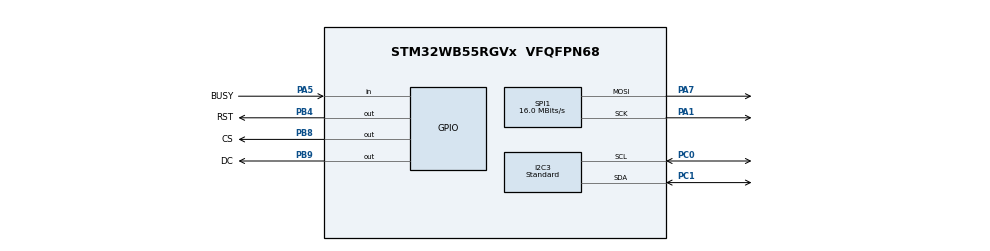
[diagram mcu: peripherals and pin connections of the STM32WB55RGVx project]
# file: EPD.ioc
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Dma.Request0=SPI1_TX
Dma.SPI1_TX.0.Direction=DMA_MEMORY_TO_PERIPH
Dma.SPI1_TX.0.EventEnable=DISABLE
Dma.SPI1_TX.0.Instance=DMA1_Channel1
Dma.SPI1_TX.0.MemDataAlignment=DMA_MDATAALIGN_BYTE
Dma.SPI1_TX.0.MemInc=DMA_MINC_ENABLE
Dma.SPI1_TX.0.Mode=DMA_NORMAL
Dma.SPI1_TX.0.PeriphDataAlignment=DMA_PDATAALIGN_BYTE
Dma.SPI1_TX.0.PeriphInc=DMA_PINC_DISABLE
Dma.SPI1_TX.0.Polarity=HAL_DMAMUX_REQ_GEN_RISING
Dma.SPI1_TX.0.Priority=DMA_PRIORITY_VERY_HIGH
Dma.SPI1_TX.0.RequestNumber=1
Dma.SPI1_TX.0.SignalID=NONE
Dma.SPI1_TX.0.SyncEnable=DISABLE
Dma.SPI1_TX.0.SyncPolarity=HAL_DMAMUX_SYNC_NO_EVENT
Dma.SPI1_TX.0.SyncRequestNumber=1
Dma.SPI1_TX.0.SyncSignalID=NONE
I2C3.I2C_Speed_Mode=I2C_Standard
I2C3.Timing=0x00B07CB4
Mcu.Family=STM32WB
Mcu.Name=STM32WB55RGVx
Mcu.Package=VFQFPN68
NVIC.DMA1_Channel1_IRQn=true\:0\:0\:false\:false\:true\:false\:true\:true
NVIC.PriorityGroup=NVIC_PRIORITYGROUP_4
NVIC.RTC_WKUP_IRQn=true\:0\:0\:false\:false\:true\:true\:true\:true
NVIC.TAMP_STAMP_LSECSS_IRQn=true\:0\:0\:false\:false\:true\:true\:true\:true
OSC_IN.GPIO_Label=RCC_OSC_IN
OSC_IN.Mode=HSE-External-Oscillator
OSC_IN.Signal=RCC_OSC_IN
OSC_OUT.GPIO_Label=RCC_OSC_OUT
OSC_OUT.Mode=HSE-External-Oscillator
OSC_OUT.Signal=RCC_OSC_OUT
P-NUCLEO-WB55-NUCLEO.BUTTON=1
P-NUCLEO-WB55-NUCLEO.BUTTON2=1
P-NUCLEO-WB55-NUCLEO.BUTTON3=1
P-NUCLEO-WB55-NUCLEO.LD1=true
P-NUCLEO-WB55-NUCLEO.LD2=true
P-NUCLEO-WB55-NUCLEO.LD3=true
P-NUCLEO-WB55-NUCLEO.VCP=true
PA1.Mode=TX_Only_Simplex_Unidirect_Master
PA1.Signal=SPI1_SCK
PA11.GPIO_Label=USB_DM
PA11.Signal=USB_DM
PA12.GPIO_Label=USB_DP
PA12.Signal=USB_DP
PA13.GPIO_Label=JTMS
PA13.Mode=Serial_Wire
PA13.Signal=SYS_JTMS-SWDIO
PA14.GPIO_Label=JTCK
PA14.Mode=Serial_Wire
PA14.Signal=SYS_JTCK-SWCLK
PA5.GPIO_Label=BUSY
PA5.Signal=GPIO_Input
PA7.Mode=TX_Only_Simplex_Unidirect_Master
PA7.Signal=SPI1_MOSI
PB3.GPIO_Label=JTDO
PB3.Signal=SYS_JTDO-SWO
PB4.GPIO_Label=RST
PB4.PinState=GPIO_PIN_SET
PB4.Signal=GPIO_Output
PB6.Signal=USART1_TX
PB7.Signal=USART1_RX
PB8.GPIO_FM8=SYSCFG_FASTMODEPLUS_PB8
PB8.GPIO_Label=CS
PB8.GPIO_Speed=GPIO_SPEED_FREQ_VERY_HIGH
PB8.PinState=GPIO_PIN_SET
PB8.Signal=GPIO_Output
PB9.GPIO_FM9=SYSCFG_FASTMODEPLUS_PB9
PB9.GPIO_Label=DC
PB9.GPIO_Speed=GPIO_SPEED_FREQ_VERY_HIGH
PB9.Signal=GPIO_Output
PC0.Mode=I2C
PC0.Signal=I2C3_SCL
PC1.Mode=I2C
PC1.Signal=I2C3_SDA
PC13.GPIO_Label=SYS_WKUP2
PC13.Signal=SYS_WKUP2
PC14-OSC32_IN.GPIO_Label=RCC_OSC32_IN
PC14-OSC32_IN.Mode=LSE-External-Oscillator
PC14-OSC32_IN.Signal=RCC_OSC32_IN
PC15-OSC32_OUT.GPIO_Label=RCC_OSC32_OUT
PC15-OSC32_OUT.Mode=LSE-External-Oscillator
PC15-OSC32_OUT.Signal=RCC_OSC32_OUT
ProjectManager.HeapSize=0x4000
ProjectManager.StackSize=0x1000
ProjectManager.TargetToolchain=STM32CubeIDE
RCC.ADCFreq_Value=128000000
RCC.AHBFreq_Value=32000000
RCC.APB1Freq_Value=32000000
RCC.APB1TimFreq_Value=32000000
RCC.APB2Freq_Value=32000000
RCC.APB2TimFreq_Value=32000000
RCC.APB3Freq_Value=16000000
RCC.CortexFreq_Value=32000000
RCC.EnableCSSLSE=true
RCC.HCLKFreq_Value=32000000
RCC.HSE_VALUE=32000000
RCC.HSI48_VALUE=48000000
RCC.HSI_VALUE=16000000
RCC.MSIClockRange=RCC_MSIRANGE_10
RCC.RTCClockSelection=RCC_RTCCLKSOURCE_LSE
RCC.SMPSCLockSelection=RCC_SMPSCLKSOURCE_HSI
RCC.SMPSCLockSelectionVirtual=RCC_SMPSCLKSOURCE_HSI
RCC.SMPSCLockSelectionVirtualVirtual=RCC_SMPSCLKSOURCE_HSI
RCC.SMPSDivider=1
RCC.SYSCLKFreq_VALUE=32000000
RCC.USBFreq_Value=128000000
RCC.VCOOutputFreq_Value=256000000
SPI1.CalculateBaudRate=16.0 MBits/s
SPI1.DataSize=SPI_DATASIZE_8BIT
SPI1.Direction=SPI_DIRECTION_2LINES
SPI1.Mode=SPI_MODE_MASTER
SPI1.NSSPMode=SPI_NSS_PULSE_DISABLE
SPI1.VirtualType=VM_MASTER
VP_MEMORYMAP_VS_MEMORYMAP.Mode=CurAppReg
VP_P-NUCLEO-WB55-NUCLEO_VS_BSP_COMMON.Mode=COMMON
VP_RTC_VS_RTC_Activate.Mode=RTC_Enabled
VP_RTC_VS_RTC_WakeUp_intern.Mode=WakeUp
board=P-NUCLEO-WB55-NUCLEO

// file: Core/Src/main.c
/* USER CODE BEGIN Header */
/**
  ******************************************************************************
  * @file           : main.c
  * @brief          : Main program body
  ******************************************************************************
  * @attention
  *
  * Copyright (c) 2025 STMicroelectronics.
  * All rights reserved.
  *
  * This software is licensed under terms that can be found in the LICENSE file
  * in the root directory of this software component.
  * If no LICENSE file comes with this software, it is provided AS-IS.
  *
  ******************************************************************************
  */
/* USER CODE END Header */
#include "main.h"

/* USER CODE BEGIN Includes */
#include <stdint.h>
#include <stdbool.h>
#include <string.h>
#include "lvgl.h"
/* USER CODE END Includes */

/* USER CODE BEGIN PD */
// Function Prototypes
void EPD_Delay_ms(uint32_t ms);
void EPD_Read_Busy(void);
void EPD_Write_Command(uint8_t command);
void EPD_Write_Data(uint8_t data);
void EPD_Init(void); // New Initialization function
void EPD_Update_and_Deepsleep_full_update(void);
void EPD_Test_Sequence(void);
void enter_stop2_mode(void);

// SHT45 I2C Driver
#define SHT45_I2C_ADDRESS 0x44
#define SHT45_CMD_MEASURE_HIGH_PRECISION 0xFD

HAL_StatusTypeDef SHT45_Read_Temp_Humidity(float *temperature, float *humidity);
/* USER CODE END PD */

COM_InitTypeDef BspCOMInit;
I2C_HandleTypeDef hi2c3;

RTC_HandleTypeDef hrtc;

SPI_HandleTypeDef hspi1;
DMA_HandleTypeDef hdma_spi1_tx;

/* USER CODE BEGIN PV */
static volatile int update_chunks_remaining = 0;
static volatile bool full_update_in_progress = false;
static uint32_t last_sensor_read_time = 0;
static float current_temperature = 0.0f;
static float current_humidity = 0.0f;
/* USER CODE END PV */

void SystemClock_Config(void);
void PeriphCommonClock_Config(void);
static void MX_GPIO_Init(void);
static void MX_DMA_Init(void);
static void MX_SPI1_Init(void);
static void MX_RTC_Init(void);
static void MX_I2C3_Init(void);

/* USER CODE BEGIN 0 */

/* LVGL EPD Display Driver */
static lv_disp_drv_t disp_drv;
static lv_disp_draw_buf_t draw_buf;
static lv_color_t buf_1[250 * 122]; /* Display buffer - 250 pixels wide, 122 lines */

/**
  * @brief  Flush the content of the internal buffer to the EPD
  * @param  drv: pointer to a display driver
  * @param  area: pointer to the area to flush
  * @param  color_p: pointer to the color data
  * @retval None
  */
void lv_epd_flush(lv_disp_drv_t * drv, const lv_area_t * area, lv_color_t * color_p)
{
    printf("LVGL Flush: Area (%d,%d)-(%d,%d) Size: %dx%d\n",
           area->x1, area->y1, area->x2, area->y2,
           area->x2 - area->x1 + 1, area->y2 - area->y1 + 1);

    uint32_t x, y;
    uint32_t width = area->x2 - area->x1 + 1;
    uint32_t height = area->y2 - area->y1 + 1;

    // EPD configuration: 122H (horizontal) packed into bytes, 250V (vertical)
    // LVGL buffer: 122V x 250H (rotated 90 degrees)
    const uint32_t EPD_BYTES_PER_LINE = 16; // 122 pixels / 8 = 15.25 -> 16 bytes

    EPD_Init();
    EPD_Write_Command(0x24); /* Write Black/White RAM */

    // Rotate 90 degrees: LVGL (122V x 250H) -> EPD (122H x 250V)
    // LVGL: top-to-bottom, left-to-right
    // EPD: bottom-up, right-to-left (landscape mode)

    // For each vertical line in EPD (250 lines)
    for(y = 0; y < 250; y++) {
        // For each byte in the horizontal line (16 bytes for 122 pixels)
        for(x = 0; x < EPD_BYTES_PER_LINE; x++) {
            uint8_t byte_data = 0;
            uint32_t bit_pos;

            // Process 8 bits per byte
            for(bit_pos = 0; bit_pos < 8; bit_pos++) {
                uint32_t pixel_x_in_epd = (x * 8 + bit_pos);

                // Only process valid pixels within 122 horizontal range
                if (pixel_x_in_epd < 122) {
                    // 90-degree rotation mapping:
                    // LVGL x coordinate becomes EPD y coordinate (rotated)
                    // LVGL y coordinate becomes EPD x coordinate (rotated)

                    // Map EPD coordinates to LVGL coordinates:
                    // EPD x (0-121) -> LVGL y (0-121)
                    // EPD y (0-249) -> LVGL x (0-249)

                    // For bottom-up, right-to-left EPD:
                    // - Reverse Y direction (bottom-up): 249 - y
                    // - Reverse X direction (right-to-left): 121 - pixel_x_in_epd

                    uint32_t lvgl_x = 249 - y;  // Reverse Y for bottom-up
                    uint32_t lvgl_y = 121 - pixel_x_in_epd;  // Reverse X for right-to-left

                    // Check if the mapped coordinates are within the current flush area
                    if (lvgl_x >= area->x1 && lvgl_x <= area->x2 &&
                        lvgl_y >= area->y1 && lvgl_y <= area->y2) {

                        // Calculate buffer index in LVGL buffer
                        uint32_t buffer_index = (lvgl_y - area->y1) * width + (lvgl_x - area->x1);

                        if (buffer_index < width * height) {
                            lv_color_t pixel_color = color_p[buffer_index];

                            /* Convert LVGL color to monochrome (1 = white, 0 = black) */
                            if(pixel_color.full != 0) { /* White */
                                // MSB first bit packing
                                byte_data |= (1 << (7 - bit_pos));
                            }
                        }
                    }
                }
            }
            EPD_Write_Data(byte_data);
        }
    }

    EPD_Update_and_Deepsleep_full_update();
    lv_disp_flush_ready(drv);
}

/**
  * @brief  Initialize LVGL with EPD display driver
  * @retval None
  */
void lv_epd_init(void)
{
    /* Debug output */
    printf("Initializing LVGL with EPD driver...\n");

    /* Initialize LVGL */
    lv_init();

    /* Initialize display buffer */
    lv_disp_draw_buf_init(&draw_buf, buf_1, NULL, 250 * 122);

    /* Initialize display driver */
    lv_disp_drv_init(&disp_drv);
    disp_drv.hor_res = 250;
    disp_drv.ver_res = 122;
    disp_drv.flush_cb = lv_epd_flush;
    disp_drv.draw_buf = &draw_buf;
    disp_drv.full_refresh = 1; /* Use full refresh until basic display works */
    disp_drv.direct_mode = 0;

    /* Register the display driver */
    lv_disp_t * disp = lv_disp_drv_register(&disp_drv);

    /* Debug output */
    printf("LVGL display driver registered. Resolution: %dx%d\n", disp_drv.hor_res, disp_drv.ver_res);

    /* Set EPD to monochrome mode */
    lv_disp_set_theme(disp, lv_theme_mono_init(disp, false, LV_FONT_DEFAULT));
}

/**
  * @brief  LVGL task handler - call this periodically in main loop
  * @retval None
  */
void lv_epd_task_handler(void)
{
    static uint32_t counter = 0;
    if(counter++ % 100 == 0) {
        printf("LVGL task handler running...\n");
    }
    lv_task_handler();
}

/**
  * @brief  Create a simple test UI for EPD
  * @retval None
  */
void lv_epd_create_test_ui(void)
{
    /* Debug output */
    printf("Creating LVGL test UI...\n");

    /* Create a simple label */
    lv_obj_t * label = lv_label_create(lv_scr_act());
    lv_label_set_text(label, "Hello");
    lv_obj_set_style_text_font(label, &lv_font_montserrat_16, 0);
    lv_obj_align(label, LV_ALIGN_CENTER, 0, 0);

}

// ... (Private macros and variables remain the same) ...
// ... (EPD_Delay_ms, EPD_Read_Busy, EPD_Write_Command, EPD_Write_Data functions remain the same) ...

/**
  * @brief  Initializes the EPD driver with the required sequence from the datasheet.
  *         This function follows the flow described in section 10.2 of the specification.
  * @retval None
  */
void EPD_Init(void)
{
    // --- 1. HARDWARE RESET SEQUENCE ---
	EPD_Delay_ms(1); // delay >200us
    HAL_GPIO_WritePin(RST_GPIO_Port, RST_Pin, GPIO_PIN_RESET); // RES# low
    EPD_Delay_ms(1); // delay >200us
    HAL_GPIO_WritePin(RST_GPIO_Port, RST_Pin, GPIO_PIN_SET);   // RES# high
    EPD_Delay_ms(1); // delay >200us
    EPD_Read_Busy(); // Wait for busy low

    // --- 2. SOFTWARE RESET ---
    EPD_Write_Command(0x12); // SWRESET command
    EPD_Read_Busy();         // Wait for busy low

    // --- 3. DRIVER OUTPUT CONTROL (Command 0x01) ---
    // Sets the panel resolution: (122-1) for Gate, (250-1) for Source
    // The panel resolution is 122(H)x250(V). This is where the original code was likely incorrect.
    EPD_Write_Command(0x01);
    EPD_Write_Data(Y_Addr_Start_L); // 121 lines (0-121)
    EPD_Write_Data(Y_Addr_Start_H); // Low byte
    EPD_Write_Data(0x00);

    // --- 4. DATA ENTRY MODE SETTING (Command 0x11) ---
    // Sets the address counter auto-increment/decrement direction. Default is 0x01, but 0x03 is common for landscape mode
    EPD_Write_Command(0x11);
    EPD_Write_Data(0x01); // Y increment, X increment

    // --- 5. SET RAM X ADDRESS START/END POSITION (Command 0x44) ---
    // Starts at 0, ends at 250/8 - 1 = 31 (0x1F) bytes
    EPD_Write_Command(0x44);
    EPD_Write_Data(X_Addr_Start);
    EPD_Write_Data(X_Addr_End); // 31

    // --- 6. SET RAM Y ADDRESS START/END POSITION (Command 0x45) ---
    // Starts at 0, ends at 122-1 = 121 (0x79)
    EPD_Write_Command(0x45);
    EPD_Write_Data(Y_Addr_Start_L);
    EPD_Write_Data(Y_Addr_Start_H); // Start Y
    EPD_Write_Data(Y_Addr_End_L); // 121 (0x79)
    EPD_Write_Data(Y_Addr_End_H); // End Y high byte

    EPD_Write_Command(0x4E);        //Set RAM X address counter
    EPD_Write_Data(X_Addr_Start);

    EPD_Write_Command(0x4F);        //Set RAM Y address counter
    EPD_Write_Data(Y_Addr_Start_L);
    EPD_Write_Data(Y_Addr_Start_H);

    // --- 7. BORDER WAVEFORM CONTROL (Command 0x3C) ---
    // Typically set to Hi-Z to prevent artifacts at the edges
    EPD_Write_Command(0x3C);
    EPD_Write_Data(0x05); // C0h sets VBD as HIZ

    EPD_Write_Command(0x21);
    EPD_Write_Data(0x00);
    EPD_Write_Data(0x00);

    EPD_Read_Busy(); // Wait for busy low

}

void EPD_Init_Partial(void) {
	EPD_Delay_ms(10);
    HAL_GPIO_WritePin(RST_GPIO_Port, RST_Pin, GPIO_PIN_RESET); // RES# low
    EPD_Delay_ms(10); // delay >200us
    HAL_GPIO_WritePin(RST_GPIO_Port, RST_Pin, GPIO_PIN_SET);   // RES# high
    EPD_Delay_ms(10); // delay >200us
    EPD_Read_Busy(); // Wait for busy low

    EPD_Write_Command(0x3C); // border folating
    EPD_Write_Data(0x80);

    EPD_Read_Busy(); // Wait for busy low
}

void EPD_Update_and_Deepsleep_full_update(void)
{
	EPD_Write_Command(0x22);
	EPD_Write_Data(0xF7);
	EPD_Write_Command(0x20);
	EPD_Read_Busy();

	EPD_Write_Command(0x10);
	EPD_Write_Data(0x01);
	EPD_Delay_ms(100);
}

void Epaper_Update_and_Deepsleep_partial_update(void) {

	EPD_Write_Command(0x22);
	EPD_Write_Data(0xFF);
	EPD_Write_Command(0x20);
	EPD_Read_Busy();

	EPD_Write_Command(0x10);
	EPD_Write_Data(0x01);
	EPD_Delay_ms(100);
}

/**
  * @brief  Provides a delay in milliseconds.
  * @param  ms: delay time in ms.
  * @retval None
  */
void EPD_Delay_ms(uint32_t ms)
{
    HAL_Delay(ms);
}

/**
  * @brief  Waits for the EPD busy signal to go low.
  * @retval None
  */
void EPD_Read_Busy(void)
{
    // The EPD outputs HIGH when busy, MCU waits for LOW
    while(HAL_GPIO_ReadPin(BUSY_GPIO_Port, BUSY_Pin) == GPIO_PIN_SET)
    {
        EPD_Delay_ms(1);
    }
}

/**
  * @brief  Sends a command to the EPD via SPI.
  * @param  command: The command byte to send.
  * @retval None
  */
void EPD_Write_Command(uint8_t command)
{
    HAL_GPIO_WritePin(CS_GPIO_Port, CS_Pin, GPIO_PIN_RESET);      // CS low (enable chip)
    HAL_GPIO_WritePin(DC_GPIO_Port, DC_Pin, GPIO_PIN_RESET);      // D/C# low (command mode)
    HAL_SPI_Transmit(&hspi1, &command, 1, 100);                           // Transmit the command
    HAL_GPIO_WritePin(CS_GPIO_Port, CS_Pin, GPIO_PIN_SET);        // CS high (disable chip select after transfer)
}

/**
  * @brief  Sends data to the EPD via SPI.
  * @param  data: The data byte to send.
  * @retval None
  */
void EPD_Write_Data(uint8_t data)
{
    HAL_GPIO_WritePin(CS_GPIO_Port, CS_Pin, GPIO_PIN_RESET);      // CS low (enable chip)
    HAL_GPIO_WritePin(DC_GPIO_Port, DC_Pin, GPIO_PIN_SET);        // D/C# high (data mode)
    HAL_SPI_Transmit(&hspi1, &data, 1, 100);                              // Transmit the data
    HAL_GPIO_WritePin(CS_GPIO_Port, CS_Pin, GPIO_PIN_SET);        // CS high
}

/**
  * @brief  Runs a basic test sequence to display an image on the EPD.
  *         This function follows the flow described in section 10.2.
  * @retval None
  */
void EPD_Test_Sequence(void)
{
    // A simple test buffer: 4000 bytes (all black display)
    // 0x00 for black pixel, 0xFF for white pixel in RAM for BW command 0x24
    uint8_t image_buffer[ALLSCREEN_BYTES] = {
    		0xff, 0xff, 0xff, 0xff, 0xff, 0xff, 0xff, 0xff, 0xff, 0xff, 0xff, 0xff, 0xff, 0xff, 0xff, 0xff,
    		0xff, 0xff, 0xff, 0xff, 0xff, 0xff, 0xff, 0xff, 0xff, 0xff, 0xff, 0xff, 0xff, 0xff, 0xff, 0xff,
    		0xff, 0xff, 0xff, 0xff, 0xff, 0xff, 0xff, 0xff, 0xff, 0xff, 0xff, 0xff, 0xff, 0xff, 0xff, 0xff,
    		0xff, 0xff, 0xff, 0xff, 0xff, 0xff, 0xff, 0xff, 0xff, 0xff, 0xff, 0xff, 0xff, 0xff, 0xff, 0xff,
    		0xff, 0xff, 0xff, 0xff, 0xff, 0xff, 0xff, 0xff, 0xff, 0xff, 0xff, 0xff, 0xff, 0xff, 0xff, 0xff,
    		0xff, 0xff, 0xff, 0xff, 0xff, 0xff, 0xff, 0xff, 0xff, 0xff, 0xff, 0xff, 0xff, 0xff, 0xff, 0xff,
    		0xff, 0xff, 0xff, 0xff, 0xff, 0xff, 0xff, 0xff, 0xff, 0xff, 0xff, 0xff, 0xff, 0xff, 0xff, 0xff,
    		0xff, 0xff, 0xff, 0xff, 0xff, 0xff, 0xff, 0xff, 0xff, 0xff, 0xff, 0xff, 0xff, 0xff, 0xff, 0xff,
    		0xfe, 0xef, 0x7d, 0xef, 0xff, 0xff, 0xff, 0xff, 0xff, 0xff, 0xff, 0xff, 0xff, 0xff, 0xff, 0xff,
    		0xff, 0xff, 0xf7, 0xff, 0x6e, 0xf7, 0xff, 0xff, 0xff, 0xff, 0xff, 0xef, 0xbf, 0x7d, 0xef, 0x7b,
    		0xff, 0xff, 0xff, 0xff, 0xff, 0xff, 0xbd, 0xef, 0x7b, 0xf7, 0xf7, 0xbf, 0xfb, 0xf7, 0xff, 0xff,
    		0xfb, 0xfb, 0xff, 0xff, 0xff, 0xff, 0xff, 0xff, 0xff, 0xff, 0xdf, 0xff, 0xff, 0xff, 0xff, 0xff,
    		0xff, 0xdf, 0xff, 0xf7, 0xff, 0xff, 0xff, 0xff, 0xff, 0xff, 0xff, 0xff, 0xff, 0xff, 0xff, 0xff,
    		0xff, 0xff, 0xdf, 0xdf, 0xff, 0xff, 0xff, 0xff, 0xff, 0xff, 0xff, 0xff, 0xff, 0xff, 0xfe, 0xef,
    		0xff, 0xff, 0xff, 0x7f, 0xff, 0xff, 0xff, 0xff, 0xff, 0xff, 0xff, 0xff, 0xff, 0xff, 0xf7, 0xff,
    		0xff, 0xff, 0xfd, 0xff, 0xdf, 0xff, 0xff, 0xff, 0xff, 0xff, 0xff, 0xff, 0xff, 0xff, 0xdf, 0xff,
    		0xfb, 0xbe, 0xff, 0xff, 0xff, 0x7f, 0xff, 0xff, 0xff, 0xff, 0xff, 0xff, 0xff, 0xff, 0xff, 0xff,
    		0xff, 0xff, 0xff, 0xff, 0xff, 0xff, 0xff, 0xff, 0xff, 0xff, 0xff, 0xff, 0xff, 0xff, 0xff, 0xfb,
    		0xff, 0xff, 0xf7, 0xff, 0xff, 0xff, 0xff, 0xff, 0xff, 0xff, 0xff, 0xff, 0xff, 0xfb, 0xff, 0xef,
    		0xff, 0xfb, 0xff, 0xff, 0xff, 0xff, 0xff, 0xff, 0xd1, 0x3f, 0xff, 0xff, 0xff, 0xff, 0xff, 0xff,
    		0xff, 0xff, 0xff, 0xff, 0xff, 0xff, 0xff, 0xf0, 0xff, 0xe0, 0x3f, 0xff, 0xff, 0xff, 0xff, 0xff,
    		0xf7, 0x7f, 0xdf, 0xff, 0xff, 0xff, 0xff, 0x8f, 0xdb, 0x7f, 0xc3, 0xff, 0xff, 0xff, 0xff, 0xff,
    		0xff, 0xff, 0xff, 0xff, 0xff, 0xff, 0xfc, 0xfe, 0xed, 0xad, 0xbc, 0xff, 0xff, 0xff, 0xff, 0xff,
    		0xff, 0xff, 0xff, 0xff, 0xff, 0xff, 0xf3, 0xf7, 0x56, 0xd6, 0xef, 0x1f, 0xff, 0xff, 0xff, 0xff,
    		0xff, 0xfd, 0xff, 0xff, 0xff, 0xff, 0xcf, 0xad, 0xbb, 0x7b, 0x5a, 0xe7, 0xff, 0xff, 0xff, 0xff,
    		0xff, 0xf7, 0xff, 0xff, 0xff, 0xff, 0x3e, 0xf6, 0xdd, 0xad, 0xb7, 0x69, 0xff, 0xff, 0xff, 0xff,
    		0xff, 0xdf, 0xff, 0xff, 0xff, 0xfc, 0xfb, 0x5b, 0x6b, 0x76, 0xda, 0xba, 0x7f, 0xff, 0xff, 0xff,
    		0xfb, 0xff, 0xff, 0xff, 0xff, 0xfb, 0xed, 0xb5, 0xb5, 0xab, 0x6d, 0xd5, 0x9f, 0xff, 0xff, 0xff,
    		0xff, 0xff, 0xff, 0xff, 0xff, 0xe7, 0xb6, 0xde, 0xde, 0xdd, 0xb6, 0xb4, 0x67, 0xff, 0xff, 0xff,
    		0xff, 0xff, 0xff, 0xff, 0xff, 0xde, 0xdb, 0x6b, 0x6b, 0x6a, 0xdb, 0x5e, 0x1b, 0xff, 0xff, 0xff,
    		0xff, 0xff, 0xff, 0xff, 0xff, 0x3d, 0xb6, 0xdd, 0xbd, 0xbd, 0x6d, 0xeb, 0x44, 0xff, 0xff, 0xff,
    		0xff, 0xff, 0xff, 0xff, 0xfe, 0xf7, 0x6d, 0xb6, 0xd6, 0xd7, 0xb6, 0xb5, 0x13, 0x7f, 0xff, 0xff,
    		0xff, 0xff, 0xff, 0xff, 0xfd, 0xfb, 0xb6, 0xdb, 0x7b, 0x7a, 0xdb, 0x5b, 0x84, 0xbf, 0xff, 0xfe,
    		0xff, 0xff, 0x7f, 0xff, 0xfb, 0xd6, 0xdb, 0x6d, 0xad, 0xad, 0x6d, 0xd5, 0x50, 0x5f, 0xff, 0xf9,
    		0xff, 0xff, 0x3f, 0xff, 0xf7, 0xbb, 0x76, 0xd6, 0xf6, 0xf7, 0xb6, 0xba, 0x85, 0x2f, 0xff, 0xf7,
    		0xff, 0xff, 0x9f, 0xff, 0xef, 0x6d, 0xad, 0xbb, 0x5b, 0x5a, 0xdb, 0x57, 0xd0, 0x17, 0xff, 0xcd,
    		0xff, 0xff, 0xe7, 0xff, 0xdd, 0xde, 0xf6, 0xdd, 0xed, 0xef, 0x6d, 0xba, 0xa2, 0x8b, 0xff, 0xbd,
    		0xff, 0xfd, 0x53, 0xff, 0xbe, 0xeb, 0x5b, 0x6e, 0xb6, 0xb5, 0xb6, 0xd5, 0x50, 0x25, 0xfe, 0x76,
    		0xff, 0xfd, 0xfc, 0xff, 0x75, 0xbd, 0xed, 0xb5, 0xdb, 0xde, 0xdb, 0x6e, 0xe5, 0x0a, 0xfd, 0xd5,
    		0xff, 0xfd, 0xaa, 0x7e, 0xfb, 0x56, 0xb6, 0xde, 0xad, 0x6b, 0x6d, 0xb5, 0x50, 0x43, 0x7b, 0x5b,
    		0xff, 0xfd, 0xb7, 0xbd, 0xd6, 0xfb, 0xdb, 0x6b, 0xf7, 0xbd, 0xb6, 0xdb, 0xb2, 0x28, 0xb6, 0x6c,
    		0xff, 0xfd, 0xd0, 0x8b, 0xfb, 0xad, 0x6d, 0xbd, 0x5a, 0xd6, 0xdb, 0x6d, 0x51, 0x01, 0x49, 0xaa,
    		0xff, 0xfd, 0x7a, 0x67, 0xae, 0xf7, 0xb6, 0xd7, 0xef, 0x7b, 0x6d, 0xb6, 0xe8, 0xa4, 0x54, 0xb6,
    		0xff, 0xfd, 0xd5, 0x27, 0xdb, 0x5a, 0xdb, 0x7a, 0xb5, 0xad, 0xb6, 0xdb, 0x5a, 0x10, 0x21, 0xd8,
    		0xff, 0xfd, 0xb4, 0xae, 0xb5, 0xef, 0x6d, 0xaf, 0xde, 0xf6, 0xdb, 0x6d, 0xa8, 0x85, 0x11, 0x6c,
    		0xff, 0xfd, 0xda, 0x1f, 0xde, 0xb5, 0xb6, 0xf5, 0x6b, 0x5b, 0x6d, 0xb6, 0xd4, 0x50, 0x40, 0xb0,
    		0xff, 0xff, 0x68, 0x1d, 0x77, 0xde, 0xdb, 0x5f, 0xbd, 0xed, 0xb6, 0xdb, 0x7a, 0x04, 0x08, 0xa0,
    		0xff, 0xfe, 0xb5, 0x3e, 0xda, 0xab, 0x6d, 0xea, 0xd6, 0xb6, 0xdb, 0x6d, 0xa9, 0x51, 0x20, 0x40,
    		0xff, 0xfe, 0xd8, 0x75, 0xad, 0xfd, 0xb6, 0xbf, 0x7b, 0xdb, 0x6d, 0xb6, 0xdc, 0x00, 0x04, 0x00,
    		0xff, 0xfe, 0x2a, 0x7e, 0xf6, 0xae, 0xdb, 0xd5, 0xad, 0x6d, 0xb6, 0xdb, 0x6a, 0x95, 0x50, 0x00,
    		0xff, 0xfe, 0x80, 0xeb, 0x5b, 0xf5, 0x6d, 0x7e, 0xf7, 0xb6, 0xdb, 0x6d, 0xac, 0x40, 0x00, 0x00,
    		0xff, 0xff, 0x51, 0xdd, 0xed, 0x5f, 0xb7, 0xab, 0x5a, 0xdb, 0x6d, 0xb6, 0xd6, 0x14, 0x90, 0x01,
    		0xff, 0xff, 0x09, 0xeb, 0x57, 0xaa, 0xda, 0xfd, 0xef, 0x6d, 0xb6, 0xdb, 0x6a, 0x80, 0x04, 0x01,
    		0xff, 0xff, 0xc3, 0xbd, 0xba, 0xff, 0x6f, 0x56, 0xb5, 0xb6, 0xdb, 0x6d, 0xb6, 0x55, 0x50, 0x01,
    		0xff, 0xff, 0x83, 0x6a, 0xd7, 0x55, 0xb5, 0xfb, 0xde, 0xdb, 0x6d, 0xb6, 0xdb, 0x00, 0x01, 0x03,
    		0xff, 0xff, 0xa7, 0xb7, 0x7a, 0xfa, 0xde, 0xad, 0x6b, 0x6d, 0xb6, 0xdb, 0x6d, 0x24, 0x94, 0x03,
    		0xff, 0xff, 0xc6, 0xda, 0xaf, 0x57, 0x6b, 0xf7, 0xbd, 0xb6, 0xdb, 0x6d, 0x55, 0x10, 0x00, 0x43,
    		0xff, 0xff, 0xcd, 0x6f, 0xf5, 0xea, 0xbd, 0x5a, 0xd6, 0xdb, 0x6d, 0xb6, 0xdb, 0x45, 0x50, 0x03,
    		0xff, 0xff, 0xef, 0xb5, 0x5e, 0xbf, 0xd7, 0xef, 0x7b, 0x6d, 0xb6, 0xdb, 0x6c, 0x10, 0x04, 0xa7,
    		0xff, 0xff, 0xda, 0xde, 0xd5, 0xd5, 0x7a, 0xb5, 0xad, 0xb6, 0xdb, 0x6d, 0xb7, 0x42, 0x40, 0x03,
    		0xff, 0xff, 0xad, 0x6b, 0x7a, 0xb7, 0xaf, 0xde, 0xf6, 0xdb, 0x6d, 0xb6, 0xda, 0x88, 0x14, 0x97,
    		0xff, 0xff, 0xb7, 0xb5, 0xaf, 0xda, 0xf5, 0x6b, 0x5b, 0x6d, 0xb6, 0xdb, 0x6d, 0xe2, 0x80, 0x17,
    		0xff, 0xff, 0x6d, 0x5e, 0xf5, 0x6d, 0x5e, 0xbd, 0xed, 0xb6, 0xd5, 0x6d, 0xb6, 0xb0, 0x2a, 0x53,
    		0xff, 0xff, 0x5b, 0xeb, 0x5d, 0xb7, 0xab, 0xd6, 0xb6, 0xdb, 0x5f, 0xb6, 0xdb, 0x59, 0x00, 0x17,
    		0xff, 0xfe, 0xed, 0x5d, 0xaa, 0xda, 0xf5, 0x7b, 0xdb, 0x6d, 0x6a, 0xdb, 0x6d, 0xec, 0x49, 0x43,
    		0xff, 0xfd, 0xbb, 0xea, 0xd7, 0x6d, 0x5f, 0xad, 0x6d, 0xb5, 0x5d, 0x6d, 0xb6, 0xb4, 0x20, 0x1b,
    		0xff, 0xfd, 0xd6, 0xbf, 0x75, 0xb7, 0x55, 0x77, 0xb6, 0xda, 0xeb, 0xb6, 0xdb, 0xda, 0x85, 0x0b,
    		0xff, 0xfd, 0x6d, 0xd5, 0xaa, 0xda, 0xae, 0xaa, 0xdb, 0x55, 0x7d, 0x5b, 0x6d, 0x6e, 0x20, 0x4b,
    		0xff, 0xfd, 0x16, 0xbe, 0xfe, 0xad, 0xd5, 0xff, 0x6d, 0x6b, 0xaa, 0xed, 0xb7, 0xb4, 0x89, 0x1b,
    		0xff, 0xfd, 0x01, 0x55, 0x55, 0x6a, 0xae, 0xaa, 0xb6, 0xa5, 0x6b, 0x76, 0xda, 0xda, 0x00, 0x4b,
    		0xff, 0xfd, 0x40, 0x3f, 0xff, 0xb7, 0x45, 0xb7, 0xd5, 0x8b, 0xad, 0xab, 0x6f, 0x60, 0xaa, 0x0b,
    		0xff, 0xfd, 0x00, 0x02, 0xaa, 0xda, 0xa6, 0xda, 0xaa, 0x8d, 0x56, 0xfd, 0xb5, 0x14, 0x00, 0x9b,
    		0xff, 0xfd, 0x40, 0x01, 0xf7, 0x6b, 0xc3, 0x6d, 0x6d, 0x15, 0x7b, 0x56, 0xd8, 0x81, 0x24, 0x0b,
    		0xff, 0xfd, 0x00, 0x00, 0x2a, 0xbc, 0xa2, 0xb6, 0xb4, 0x15, 0xad, 0xfb, 0x40, 0x00, 0x01, 0x2b,
    		0xff, 0xfd, 0x80, 0x00, 0x1f, 0xd7, 0x43, 0x5b, 0x52, 0x36, 0xf6, 0xac, 0x00, 0x00, 0x54, 0x0b,
    		0xff, 0xfd, 0x20, 0x88, 0x05, 0x7a, 0xa9, 0xaa, 0xa8, 0x55, 0x5b, 0xf0, 0x00, 0x00, 0x00, 0x2b,
    		0xff, 0xfd, 0x80, 0x24, 0x03, 0xaf, 0xc1, 0x6d, 0x41, 0x5f, 0xed, 0x40, 0x00, 0x00, 0x05, 0x0b,
    		0xff, 0xfe, 0x82, 0x10, 0x00, 0xf5, 0x7a, 0xb5, 0x28, 0xaa, 0xb7, 0x00, 0x00, 0x00, 0x00, 0x0b,
    		0xff, 0xfe, 0x00, 0xb0, 0x20, 0x5e, 0xad, 0xda, 0xaf, 0x7f, 0xda, 0x00, 0x03, 0x00, 0x08, 0x0b,
    		0xff, 0xfe, 0x00, 0x30, 0x60, 0x2b, 0xf6, 0xad, 0xb5, 0xaa, 0xac, 0x00, 0x23, 0x80, 0x00, 0x0b,
    		0xff, 0xfe, 0x02, 0x70, 0xf8, 0x1d, 0x5b, 0x76, 0xda, 0xf7, 0xf0, 0x04, 0xd1, 0x00, 0x00, 0x0b,
    		0xff, 0xfe, 0x00, 0x20, 0x18, 0x07, 0xad, 0xab, 0x6f, 0x5a, 0xa0, 0x0e, 0xd1, 0x80, 0x00, 0x0b,
    		0xff, 0xfe, 0x01, 0x30, 0x18, 0x02, 0xf6, 0xdd, 0xb5, 0xef, 0x80, 0x0e, 0xd1, 0x80, 0x00, 0x03,
    		0xff, 0xfe, 0x00, 0x60, 0x00, 0x01, 0x5b, 0x6a, 0xda, 0xb4, 0x00, 0x00, 0x11, 0x80, 0x00, 0x03,
    		0xff, 0xfe, 0x02, 0x30, 0x00, 0x01, 0x6d, 0xb7, 0x6f, 0x5c, 0x00, 0x00, 0x11, 0x80, 0x00, 0x0b,
    		0xff, 0xfe, 0x00, 0x30, 0x00, 0x00, 0x35, 0x5a, 0xb5, 0xe0, 0x00, 0x00, 0x11, 0x90, 0x00, 0x0b,
    		0xff, 0xfe, 0x01, 0x30, 0x00, 0x00, 0x16, 0xed, 0xda, 0xa0, 0x00, 0x00, 0x11, 0x80, 0x00, 0x0b,
    		0xff, 0xfe, 0x00, 0x10, 0x00, 0x00, 0x05, 0x56, 0xaf, 0x40, 0x00, 0x00, 0x11, 0x80, 0x01, 0x4b,
    		0xff, 0xfe, 0xc1, 0x18, 0x00, 0x00, 0x02, 0xaa, 0xd5, 0x00, 0x00, 0x00, 0x13, 0x00, 0x04, 0x03,
    		0xff, 0xfe, 0xb0, 0x48, 0x00, 0x00, 0x00, 0x00, 0x00, 0x00, 0x00, 0x00, 0x33, 0x00, 0x68, 0xab,
    		0xff, 0xfe, 0xd2, 0x08, 0x00, 0x00, 0x00, 0x00, 0x00, 0x00, 0x00, 0x00, 0x23, 0x01, 0xa4, 0x07,
    		0xff, 0xfe, 0xec, 0x24, 0x00, 0x00, 0x00, 0x00, 0x00, 0x00, 0x00, 0x00, 0x66, 0x0e, 0xaa, 0x85,
    		0xff, 0xfe, 0xdb, 0x02, 0x00, 0x00, 0x0b, 0xbf, 0xde, 0x00, 0x00, 0x00, 0x84, 0x13, 0x55, 0x27,
    		0xff, 0xfe, 0xed, 0xc1, 0x80, 0x10, 0xee, 0xd5, 0x75, 0xe8, 0x09, 0x07, 0x04, 0x6d, 0x55, 0x05,
    		0xff, 0xfe, 0xd6, 0xb0, 0x00, 0x07, 0x5b, 0x7b, 0x5b, 0x5f, 0x40, 0x50, 0x01, 0xba, 0xaa, 0xa3,
    		0xff, 0xfe, 0xfb, 0x6d, 0x00, 0x29, 0xb6, 0xd5, 0xed, 0xea, 0xf8, 0x00, 0x0e, 0xd6, 0xa9, 0x0b,
    		0xff, 0xfe, 0xad, 0xb6, 0xd5, 0xb6, 0xed, 0xbe, 0xb6, 0xbd, 0xaf, 0xaa, 0xb5, 0x7a, 0xa5, 0x23,
    		0xff, 0xfe, 0xd6, 0xdb, 0x7a, 0xdb, 0x76, 0xd5, 0xdb, 0xab, 0x6a, 0xdb, 0x6f, 0xaa, 0xaa, 0x8b,
    		0xff, 0xfe, 0xbb, 0x6d, 0xad, 0x56, 0xdb, 0x76, 0xad, 0x75, 0xb6, 0xad, 0xb5, 0x6a, 0xaa, 0x0b,
    		0xff, 0xff, 0x2d, 0xbb, 0x77, 0x6d, 0xad, 0xab, 0xf7, 0xae, 0xdb, 0x76, 0xdb, 0xaa, 0x54, 0x0b,
    		0xff, 0xff, 0x16, 0xd6, 0xd5, 0xb6, 0xf6, 0xfd, 0x5a, 0xd0, 0x05, 0xab, 0x6c, 0xaa, 0xa0, 0x17,
    		0xff, 0xff, 0x25, 0x7b, 0x00, 0x15, 0x5b, 0x57, 0xad, 0x40, 0x00, 0x5d, 0x56, 0xaa, 0x80, 0x17,
    		0xff, 0xff, 0x89, 0x44, 0x00, 0x01, 0x01, 0xea, 0xd0, 0x0f, 0xb4, 0x02, 0xaa, 0xaa, 0x20, 0x37,
    		0xff, 0xff, 0x82, 0x20, 0x1f, 0xfe, 0x40, 0x1a, 0x01, 0xbf, 0xfe, 0x80, 0x2a, 0xa8, 0x80, 0x2f,
    		0xff, 0xff, 0xa8, 0x01, 0xff, 0xff, 0xfc, 0x00, 0x6f, 0xff, 0xff, 0xf0, 0x01, 0x40, 0x01, 0x2f,
    		0xff, 0xff, 0xc1, 0x0e, 0xff, 0xff, 0xff, 0xdb, 0xff, 0xff, 0xff, 0xfe, 0x00, 0x00, 0x00, 0x5f,
    		0xff, 0xff, 0xc4, 0x2b, 0xff, 0xff, 0xff, 0xff, 0xff, 0xff, 0xff, 0xff, 0xa0, 0x00, 0x08, 0xdf,
    		0xff, 0xff, 0xe0, 0x7f, 0xff, 0xff, 0xff, 0xff, 0xff, 0xff, 0xff, 0xff, 0xe8, 0x00, 0x20, 0xbf,
    		0xff, 0xff, 0xf1, 0xbf, 0xff, 0xff, 0xff, 0xff, 0xff, 0xff, 0xff, 0xff, 0xfa, 0x85, 0x01, 0x3f,
    		0xff, 0xff, 0xf0, 0xbf, 0xff, 0xff, 0xff, 0xff, 0xff, 0xff, 0xff, 0xff, 0xfe, 0x98, 0x4a, 0x7f,
    		0xff, 0xff, 0xf8, 0x7f, 0xff, 0xff, 0xff, 0xff, 0xff, 0xff, 0xff, 0xff, 0xfa, 0x51, 0x02, 0xff,
    		0xff, 0xff, 0xfc, 0x9f, 0xff, 0xff, 0xff, 0xff, 0xff, 0xff, 0xff, 0xff, 0xfa, 0xa0, 0x25, 0xff,
    		0xff, 0xff, 0xfe, 0x0f, 0xff, 0xff, 0xff, 0xff, 0xff, 0xff, 0xff, 0xff, 0xf5, 0x44, 0x8b, 0xff,
    		0xff, 0xff, 0xff, 0x23, 0xff, 0xff, 0xff, 0xff, 0xff, 0xff, 0xff, 0xff, 0xea, 0x10, 0x17, 0xff,
    		0xff, 0xff, 0xff, 0x88, 0xb6, 0xff, 0xff, 0xff, 0xff, 0xff, 0xff, 0xff, 0xc9, 0x02, 0x43, 0xff,
    		0xff, 0xff, 0xff, 0x00, 0x5f, 0xad, 0xff, 0xff, 0xff, 0xff, 0xff, 0xff, 0x24, 0x50, 0x00, 0xff,
    		0xff, 0xff, 0xfe, 0xe2, 0x95, 0xfb, 0x5b, 0xff, 0xff, 0xff, 0xff, 0xfc, 0x91, 0x04, 0x02, 0x7f,
    		0xff, 0xff, 0xfb, 0x80, 0x02, 0xaf, 0xff, 0x7f, 0xff, 0xff, 0xfe, 0xd0, 0x40, 0x40, 0x00, 0x1f,
    		0xff, 0xff, 0xee, 0x00, 0x11, 0x3d, 0x6a, 0xd5, 0xb6, 0xab, 0xb7, 0x45, 0x0a, 0x10, 0x01, 0x0f,
    		0xff, 0xff, 0xbc, 0x00, 0x00, 0x42, 0xd7, 0x7e, 0xdb, 0xfe, 0xe0, 0x10, 0x20, 0x80, 0x00, 0x43,
    		0xff, 0xfe, 0xf0, 0x00, 0x00, 0x00, 0x10, 0x93, 0x6d, 0x40, 0x08, 0x84, 0x80, 0x00, 0x00, 0x09,
    		0xff, 0xfb, 0xc0, 0x00, 0x00, 0x02, 0x44, 0x00, 0x00, 0x0a, 0x02, 0x20, 0x00, 0x04, 0x80, 0x20,
    		0xff, 0xf7, 0x80, 0x00, 0x00, 0x00, 0x01, 0x20, 0x00, 0x00, 0xa0, 0x00, 0x00, 0x02, 0x00, 0x04,
    		0xff, 0xde, 0x00, 0x06, 0x85, 0x00, 0x00, 0x00, 0x00, 0x40, 0x00, 0x00, 0x00, 0x7f, 0x40, 0x01,
    		0xff, 0xbc, 0x00, 0x1a, 0x0e, 0xa0, 0x00, 0x00, 0x00, 0x00, 0x00, 0x00, 0x01, 0xbf, 0xe0, 0x04,
    		0xfe, 0xf0, 0x00, 0x35, 0x9f, 0xd8, 0x00, 0x00, 0x00, 0x00, 0x00, 0x00, 0x00, 0xff, 0xf8, 0x00,
    		0xfd, 0xe0, 0x00, 0x56, 0x1f, 0xff, 0x00, 0x00, 0x00, 0x00, 0x00, 0x00, 0x02, 0xff, 0xfa, 0x00,
    		0xf7, 0x80, 0x00, 0xda, 0x3f, 0xfd, 0xf2, 0x00, 0x00, 0x00, 0x00, 0x28, 0x01, 0xff, 0xfc, 0x00,
    		0xef, 0x40, 0x01, 0xab, 0x3f, 0xff, 0x8d, 0xf4, 0xaa, 0x80, 0x9f, 0xff, 0x00, 0xff, 0xfe, 0x00,
    		0xfe, 0x00, 0x01, 0xb4, 0x7f, 0xfc, 0x0b, 0x59, 0xff, 0xe0, 0x0b, 0x6f, 0xc1, 0xff, 0xff, 0x40,
    		0x78, 0x00, 0x03, 0x5e, 0x7f, 0xe0, 0x1f, 0xab, 0xff, 0xf0, 0x41, 0xfe, 0xc0, 0xff, 0xfe, 0x80,
    		0xf0, 0x00, 0x03, 0x6a, 0x7f, 0x80, 0x3f, 0xf7, 0xff, 0xe0, 0x2a, 0x7f, 0xe0, 0xff, 0xff, 0x10,
    		0xe0, 0x00, 0x03, 0xb4, 0xfe, 0x00, 0x1f, 0xeb, 0xff, 0xf0, 0x14, 0x9f, 0xe0, 0xff, 0xfe, 0x40,
    		0xc0, 0x00, 0x06, 0xdc, 0xf8, 0x00, 0xbf, 0xef, 0xdf, 0xf0, 0x05, 0x47, 0xf0, 0x7f, 0xfe, 0x98,
    		0x00, 0x00, 0x06, 0xa8, 0xf0, 0x00, 0x3f, 0xc7, 0xbf, 0xf0, 0x0a, 0xab, 0xe8, 0x7f, 0xaa, 0x04,
    		0x00, 0x00, 0x07, 0xf5, 0xe0, 0x00, 0xbf, 0xc0, 0x1f, 0xe0, 0x04, 0x94, 0xf0, 0x5b, 0x55, 0x52,
    		0x00, 0x00, 0x05, 0x59, 0xc0, 0x00, 0x1f, 0xc0, 0x1f, 0xc0, 0x05, 0x52, 0xf0, 0x2d, 0xff, 0x86,
    		0x00, 0x00, 0x07, 0x69, 0x80, 0x00, 0x03, 0x00, 0x00, 0x00, 0x0a, 0xaa, 0x78, 0x1b, 0xff, 0xd1,
    		0x00, 0x00, 0x1e, 0xdb, 0x00, 0x00, 0x00, 0x00, 0x00, 0x00, 0x04, 0x95, 0x30, 0x2f, 0xff, 0xe1,
    		0x00, 0x00, 0x3f, 0xab, 0x00, 0x00, 0x00, 0x00, 0x00, 0x00, 0x15, 0x52, 0xb8, 0x37, 0xff, 0xe8,
    		0x00, 0x00, 0x3f, 0xf4, 0x00, 0x00, 0x00, 0x00, 0x00, 0x00, 0x2a, 0xaa, 0x58, 0x5f, 0xff, 0xe5,
    		0x00, 0x00, 0x7f, 0xaa, 0x00, 0x00, 0x00, 0x00, 0x00, 0x00, 0x49, 0x29, 0x50, 0x2b, 0xff, 0xe8,
    		0x00, 0x00, 0x7f, 0xfe, 0x00, 0x00, 0x00, 0x00, 0x00, 0x01, 0x2a, 0xa5, 0x18, 0x2f, 0xff, 0xf2,
    		0x00, 0x00, 0xff, 0xe8, 0x00, 0x00, 0x00, 0x00, 0x00, 0x04, 0xa9, 0x55, 0x40, 0x3f, 0xff, 0xe8,
    		0x00, 0x00, 0xff, 0xfc, 0x00, 0x00, 0x00, 0x00, 0x00, 0xaa, 0xa5, 0x2a, 0xa0, 0x0f, 0xff, 0xea,
    		0x00, 0x01, 0xbf, 0xf4, 0x00, 0x00, 0x00, 0x00, 0x15, 0x55, 0x55, 0x52, 0x40, 0x2f, 0xff, 0xf4,
    		0x00, 0x01, 0xff, 0xfc, 0x00, 0x00, 0x00, 0x01, 0x52, 0x4a, 0x94, 0xaa, 0x80, 0x17, 0xff, 0xe8,
    		0x00, 0x00, 0xbf, 0xf8, 0x00, 0x00, 0x00, 0x05, 0x2a, 0xa9, 0x52, 0x95, 0x40, 0x1b, 0xff, 0xe4,
    		0x00, 0x00, 0xff, 0xfc, 0x00, 0x00, 0x00, 0x04, 0xaa, 0x94, 0xaa, 0x52, 0x00, 0x0f, 0xff, 0xda,
    		0x00, 0x00, 0xbf, 0xf8, 0x7d, 0x00, 0x00, 0x05, 0x49, 0x52, 0x95, 0x49, 0x00, 0x05, 0xff, 0xe4,
    		0x00, 0x18, 0xbf, 0xfd, 0xb6, 0x81, 0xf8, 0x05, 0x25, 0x28, 0x40, 0x95, 0x08, 0x05, 0xff, 0x50,
    		0x00, 0x66, 0x5f, 0xf7, 0xff, 0xc7, 0xde, 0x09, 0x50, 0xff, 0x2f, 0xe4, 0x30, 0x02, 0xbf, 0xa4,
    		0x02, 0xb1, 0x97, 0xeb, 0xff, 0xef, 0xff, 0x04, 0xfd, 0xbf, 0xdf, 0xf2, 0x74, 0x00, 0xd4, 0x90,
    		0x04, 0x54, 0x4a, 0x53, 0xff, 0xff, 0xfd, 0x93, 0xfd, 0xff, 0xff, 0xf1, 0xe8, 0x00, 0x14, 0x01,
    		0x02, 0x54, 0x23, 0xa9, 0xff, 0xff, 0xff, 0x0b, 0xed, 0xff, 0xff, 0xf3, 0xb0, 0x00, 0x00, 0x42,
    		0x05, 0x2a, 0x00, 0x01, 0xff, 0xff, 0xff, 0xc6, 0xbf, 0xff, 0xff, 0xff, 0xe8, 0x00, 0x00, 0x0d,
    		0x00, 0xa4, 0x88, 0x01, 0xff, 0xff, 0xff, 0x9b, 0xff, 0xff, 0xff, 0xff, 0xb4, 0x00, 0x01, 0x55,
    		0x03, 0x55, 0x20, 0x01, 0xff, 0xff, 0xff, 0xcf, 0xff, 0xff, 0xff, 0xff, 0x68, 0x00, 0x10, 0x35,
    		0x18, 0x52, 0x00, 0x00, 0xff, 0xff, 0xff, 0xd5, 0xff, 0xff, 0xff, 0xfe, 0xf0, 0x00, 0x00, 0xd4,
    		0x02, 0x95, 0x52, 0x00, 0xff, 0xff, 0xff, 0xb7, 0xff, 0xff, 0xff, 0xff, 0xb4, 0x00, 0x03, 0xaa,
    		0x74, 0x52, 0x00, 0x00, 0xff, 0xff, 0xff, 0xdf, 0xff, 0xff, 0xff, 0xfd, 0xe0, 0x00, 0x06, 0xa8,
    		0x62, 0xa9, 0x48, 0x00, 0xff, 0xff, 0xff, 0xcf, 0xff, 0xff, 0xff, 0xff, 0x68, 0x00, 0x08, 0xac,
    		0x2a, 0x84, 0x00, 0x00, 0x7f, 0xff, 0xff, 0xcf, 0xff, 0xff, 0xff, 0xfb, 0xd0, 0x00, 0x15, 0x54,
    		0x94, 0xa8, 0x90, 0x00, 0x6f, 0xff, 0xff, 0xaf, 0xff, 0xff, 0xff, 0xfe, 0xa0, 0x00, 0x22, 0xaa,
    		0x72, 0xa2, 0x04, 0x00, 0x3f, 0xff, 0xff, 0x87, 0xff, 0xff, 0xff, 0xeb, 0xa0, 0x00, 0x15, 0x55,
    		0xea, 0x48, 0x90, 0x00, 0x15, 0xff, 0xfe, 0x43, 0xff, 0xff, 0xff, 0xbd, 0x40, 0x00, 0x42, 0xaa,
    		0xfb, 0x20, 0x00, 0x00, 0x0f, 0xff, 0x00, 0x00, 0x1f, 0xff, 0xff, 0xee, 0x80, 0x00, 0x0a, 0xaa,
    		0xed, 0x40, 0xa0, 0x00, 0x20, 0x00, 0xff, 0x8f, 0xf8, 0x3f, 0xfd, 0xb5, 0x00, 0x00, 0x4a, 0xb5,
    		0xd6, 0x80, 0x08, 0x00, 0x00, 0xff, 0xff, 0xcf, 0xff, 0xe0, 0x5e, 0xd8, 0x00, 0x00, 0x15, 0x55,
    		0xfb, 0x00, 0x00, 0x00, 0x30, 0x7f, 0xff, 0xef, 0xff, 0xff, 0xa1, 0x60, 0x00, 0x00, 0x2a, 0xaa,
    		0xad, 0x80, 0x10, 0x00, 0x15, 0x3f, 0xff, 0xef, 0xff, 0xff, 0xd4, 0x00, 0x00, 0x00, 0x15, 0x54,
    		0xd6, 0xa0, 0x00, 0x00, 0x1c, 0x1f, 0xff, 0xdf, 0xff, 0xff, 0x68, 0x90, 0x00, 0x00, 0x4a, 0xa2,
    		0xbb, 0x40, 0x00, 0x00, 0x0d, 0x05, 0xff, 0xcf, 0xff, 0xfe, 0xa1, 0x62, 0xd0, 0x00, 0x15, 0x54,
    		0xd5, 0x80, 0x00, 0x00, 0x06, 0x92, 0xb5, 0x63, 0xff, 0xfb, 0x0e, 0x8f, 0x00, 0x00, 0x0a, 0xa8,
    		0x6e, 0xc0, 0x00, 0x00, 0x07, 0xa0, 0x00, 0x28, 0x15, 0x54, 0x6b, 0xd8, 0x80, 0x00, 0x25, 0x55,
    		0xb5, 0x20, 0x00, 0x00, 0x02, 0xd0, 0xbf, 0xd4, 0xc4, 0x80, 0xfd, 0x5e, 0x00, 0x00, 0x05, 0x2a,
    		0xda, 0x80, 0x00, 0x00, 0x03, 0xd6, 0x00, 0x2f, 0x10, 0x54, 0xff, 0x81, 0x00, 0x00, 0x12, 0xa4,
    		0x4a, 0x20, 0x00, 0x00, 0x01, 0x72, 0xfd, 0x90, 0xc9, 0xb5, 0xbd, 0x5c, 0x00, 0x00, 0x04, 0xa8,
    		0xa0, 0x80, 0x00, 0x00, 0x02, 0xd4, 0x7f, 0xff, 0x23, 0xfc, 0xfd, 0xb2, 0x80, 0x00, 0x12, 0xa1,
    		0x00, 0x20, 0x00, 0x00, 0x02, 0x85, 0x7f, 0xff, 0x2b, 0x44, 0xfd, 0x1c, 0x00, 0x00, 0x04, 0x94,
    		0x80, 0x40, 0x00, 0x00, 0x00, 0x52, 0x7f, 0xfe, 0xab, 0xfe, 0xfd, 0xa0, 0x00, 0x00, 0x02, 0x56,
    		0x20, 0x00, 0x00, 0x00, 0x01, 0x24, 0x7f, 0xfe, 0x2b, 0xe8, 0x6d, 0x3a, 0x00, 0x00, 0x09, 0x29,
    		0x00, 0x20, 0x00, 0x00, 0x00, 0x42, 0x3f, 0xff, 0x4a, 0xbc, 0xed, 0x80, 0x00, 0x00, 0x15, 0xaa,
    		0x40, 0x00, 0x00, 0x00, 0x06, 0x05, 0x7f, 0xfd, 0x2b, 0xe4, 0x6c, 0x20, 0x00, 0x00, 0x2a, 0xb5,
    		0x01, 0x00, 0x00, 0x00, 0x0d, 0x12, 0x3f, 0xff, 0x0b, 0xfa, 0x29, 0x00, 0x00, 0x00, 0x55, 0x5a,
    		0x00, 0x00, 0x00, 0x00, 0x1a, 0x81, 0x5f, 0xff, 0x50, 0xad, 0x00, 0x00, 0x40, 0x00, 0xab, 0x6d,
    		0x42, 0x00, 0x00, 0x00, 0x3e, 0xa2, 0x7f, 0xff, 0x2b, 0xf0, 0x00, 0x05, 0x60, 0x00, 0x5a, 0xab,
    		0x10, 0x00, 0x00, 0x00, 0x7f, 0x50, 0x3f, 0xff, 0x80, 0x01, 0x00, 0x55, 0xa8, 0x01, 0xaa, 0xb5,
    		0x08, 0x00, 0x00, 0x00, 0x7f, 0xc8, 0x07, 0xff, 0x28, 0x0a, 0x00, 0xab, 0x70, 0x02, 0xf6, 0x5d,
    		0x20, 0x00, 0x00, 0x00, 0xff, 0xf0, 0x08, 0xfe, 0x40, 0xb4, 0x01, 0x5f, 0xa8, 0x05, 0x5a, 0x56,
    		0x00, 0x00, 0x00, 0x01, 0xff, 0xf8, 0x22, 0x18, 0xa5, 0x7a, 0x05, 0xff, 0x70, 0x03, 0xad, 0x03,
    		0x00, 0x00, 0x00, 0x03, 0xff, 0xfc, 0x14, 0x82, 0x97, 0xd0, 0x0b, 0xff, 0xd8, 0x00, 0xf5, 0x1d,
    		0x00, 0x00, 0x00, 0x03, 0xff, 0xfe, 0x0a, 0x28, 0x5d, 0x68, 0x1f, 0xff, 0xec, 0x01, 0x54, 0x0a,
    		0x00, 0x00, 0x00, 0x07, 0xff, 0xff, 0x05, 0x81, 0xb7, 0xa0, 0x3f, 0xff, 0xf4, 0x00, 0xad, 0x0b,
    		0x00, 0x00, 0x00, 0x07, 0xff, 0xfe, 0x81, 0x76, 0xda, 0xc0, 0x7f, 0xff, 0xf6, 0x00, 0x50, 0x15,
    		0x00, 0x00, 0x08, 0x07, 0xff, 0xff, 0x40, 0x1b, 0x77, 0x00, 0xff, 0xff, 0xf9, 0x00, 0x24, 0x2d,
    		0x00, 0x00, 0x00, 0x07, 0xff, 0xfd, 0xa0, 0x45, 0xad, 0x00, 0xff, 0xff, 0xfa, 0x00, 0x00, 0x26,
    		0x00, 0x00, 0x00, 0x0b, 0xff, 0xff, 0x40, 0x10, 0x54, 0x00, 0xff, 0xff, 0xfa, 0x80, 0x2a, 0x15,
    		0x00, 0x00, 0x00, 0x0f, 0xff, 0xfb, 0xa0, 0x05, 0x2a, 0x00, 0xff, 0xff, 0xfd, 0x00, 0x00, 0x05,
    		0x00, 0x00, 0x3e, 0x01, 0xff, 0xfd, 0xa0, 0x00, 0x40, 0x00, 0xff, 0xff, 0xfa, 0x00, 0x08, 0x25,
    		0x00, 0x00, 0x7f, 0x01, 0x7f, 0xee, 0x80, 0x00, 0x10, 0x00, 0xff, 0xff, 0xfc, 0x00, 0x00, 0x0a,
    		0x00, 0x00, 0x7f, 0x9c, 0x55, 0x5b, 0xa0, 0x00, 0x00, 0x00, 0x7f, 0xff, 0xf9, 0x00, 0x00, 0x02,
    		0x00, 0x00, 0xff, 0xcf, 0x0d, 0xf6, 0x80, 0x00, 0x00, 0x00, 0xff, 0xff, 0xe0, 0x00, 0x00, 0x11,
    		0x00, 0x00, 0xff, 0xd3, 0xe2, 0xba, 0x00, 0x00, 0x00, 0x00, 0x5f, 0xf5, 0x0a, 0x80, 0x00, 0x08,
    		0x00, 0x00, 0xff, 0xc4, 0xb8, 0x55, 0x40, 0x00, 0x00, 0x00, 0x7f, 0x50, 0xf4, 0x00, 0x00, 0x05,
    		0x00, 0x01, 0xff, 0xca, 0xaa, 0x00, 0x00, 0x00, 0x00, 0x00, 0x28, 0x0f, 0x55, 0x00, 0x00, 0x00,
    		0x00, 0x01, 0xff, 0xe1, 0x55, 0xa0, 0x00, 0x00, 0x00, 0x00, 0x10, 0xf5, 0x54, 0x40, 0x00, 0x00,
    		0x03, 0x81, 0xff, 0xe1, 0x55, 0x40, 0x00, 0x00, 0x00, 0x00, 0x03, 0x55, 0xaa, 0x00, 0x00, 0x00,
    		0x07, 0xc1, 0xff, 0xf2, 0x2a, 0x80, 0x00, 0x00, 0x00, 0x00, 0x00, 0x15, 0x54, 0x80, 0x00, 0x00,
    		0x07, 0xf1, 0xff, 0xf0, 0x00, 0x20, 0x00, 0x00, 0x00, 0x00, 0x0a, 0x95, 0x40, 0x00, 0x00, 0x00,
    		0x0f, 0xf9, 0xff, 0xf9, 0x44, 0x80, 0x00, 0x00, 0x00, 0x00, 0x00, 0x2a, 0x2a, 0x80, 0x00, 0x00,
    		0x0f, 0xfd, 0xff, 0xf8, 0x10, 0x00, 0x00, 0x00, 0x00, 0x00, 0x01, 0x04, 0x80, 0x00, 0x00, 0x00,
    		0x0f, 0xfe, 0xff, 0xfc, 0x42, 0x40, 0x00, 0x00, 0x00, 0x00, 0x00, 0x40, 0x12, 0x40, 0x00, 0x00,
    		0x0f, 0xfe, 0xff, 0xfd, 0x08, 0x00, 0x00, 0x00, 0x00, 0x00, 0x00, 0x15, 0x40, 0x00, 0x07, 0xff,
    		0x8f, 0xff, 0xff, 0xfc, 0xa1, 0x00, 0x00, 0x00, 0x00, 0x00, 0x01, 0x40, 0x05, 0x00, 0x1f, 0xff,
    		0xcf, 0xff, 0xff, 0xfc, 0xac, 0x00, 0x00, 0x00, 0x00, 0x00, 0x00, 0x00, 0x00, 0x00, 0x0f, 0xff,
    		0xef, 0xff, 0xff, 0xfc, 0x2a, 0x80, 0x00, 0x00, 0x00, 0x00, 0x00, 0x00, 0x24, 0x40, 0x0f, 0xff,
    		0xff, 0xff, 0xff, 0xfc, 0x04, 0x00, 0x00, 0x00, 0x00, 0x00, 0x00, 0x2a, 0x01, 0x00, 0x0f, 0xff,
    		0xff, 0xff, 0xff, 0xfa, 0x00, 0x40, 0x00, 0x00, 0x00, 0x00, 0x03, 0x80, 0xad, 0x50, 0x0f, 0xff,
    		0xff, 0xff, 0xff, 0xf9, 0xa1, 0x00, 0x07, 0x80, 0x00, 0x00, 0x0f, 0xc2, 0x2a, 0x80, 0x0f, 0xff,
    		0xff, 0xff, 0xff, 0xfa, 0xa8, 0x00, 0x0f, 0xe0, 0x00, 0x00, 0x3f, 0xc8, 0xaa, 0x20, 0x0f, 0xff,
    		0xff, 0xff, 0xff, 0xf0, 0xaa, 0x40, 0x0f, 0xf8, 0x00, 0x00, 0xff, 0xc0, 0x80, 0x80, 0x07, 0xff,
    		0xff, 0xff, 0xff, 0xe1, 0x55, 0x00, 0x1f, 0xff, 0x00, 0x01, 0xff, 0xc2, 0x04, 0x00, 0x03, 0xff,
    		0xff, 0xff, 0x00, 0x00, 0x2a, 0x20, 0x1f, 0xff, 0xc0, 0x03, 0xff, 0xc0, 0x10, 0x80, 0x03, 0xff,
    		0xff, 0xf8, 0x86, 0xc0, 0x8a, 0x00, 0x1f, 0xff, 0xf8, 0x07, 0xff, 0xc0, 0x42, 0x25, 0x41, 0xff,
    		0xff, 0xe2, 0x7b, 0x55, 0x02, 0x50, 0x0f, 0xff, 0xfe, 0x07, 0xff, 0xc2, 0x15, 0x50, 0x03, 0xff,
    		0xff, 0xc9, 0xaa, 0xd6, 0xd0, 0x00, 0x0f, 0xff, 0xff, 0x8f, 0xff, 0xc0, 0x95, 0x55, 0x01, 0xff,
    		0xff, 0x22, 0xdd, 0x7b, 0x49, 0x40, 0x0f, 0xff, 0xff, 0xef, 0xff, 0xc9, 0x15, 0xa4, 0x03, 0xff,
    		0xff, 0x4f, 0x67, 0xaa, 0xb0, 0x00, 0x06, 0xd5, 0x56, 0xbf, 0xff, 0xe0, 0x4a, 0xa0, 0x01, 0xff,
    		0xfe, 0x49, 0x5a, 0xad, 0xaa, 0x40, 0x00, 0x20, 0x09, 0x41, 0x12, 0x42, 0x04, 0x08, 0x00, 0xff,
    		0xfa, 0x95, 0x2d, 0x76, 0xa0, 0x00, 0x00, 0x02, 0xd2, 0x5c, 0xa9, 0x20, 0x10, 0xa1, 0x00, 0x00,
    		0xfc, 0x0a, 0x75, 0xa9, 0x55, 0x00, 0x00, 0x55, 0x29, 0x42, 0xa5, 0x41, 0x02, 0x04, 0x00, 0x00,
    		0xfd, 0x28, 0x2a, 0xaa, 0x00, 0x00, 0x55, 0x48, 0x95, 0x35, 0x55, 0x50, 0x40, 0x5b, 0xa9, 0x00,
    		0xe8, 0x12, 0x45, 0x54, 0x90, 0x02, 0x92, 0xa6, 0xa4, 0x94, 0x94, 0xa8, 0x0a, 0x55, 0x68, 0x00,
    		0x28, 0x08, 0x15, 0x40, 0x04, 0x0a, 0xa9, 0x29, 0x55, 0x52, 0xa5, 0x25, 0x23, 0xb6, 0xb7, 0x40,
    		0x92, 0x00, 0x42, 0xaa, 0x40, 0x2a, 0x4a, 0x94, 0x92, 0xaa, 0x52, 0x90, 0x0a, 0xdb, 0xad, 0x42,
    		0x55, 0x40, 0x00, 0x00, 0x02, 0xa5, 0x54, 0xa5, 0x4a, 0x49, 0x4a, 0x54, 0x05, 0x55, 0x6b, 0x50,
    		0x49, 0x5a, 0x00, 0x00, 0x54, 0x92, 0x4a, 0x94, 0xa9, 0x25, 0x29, 0x54, 0x2b, 0x6d, 0xad, 0x80,
    		0x55, 0x25, 0x6a, 0x95, 0x4a, 0x55, 0x29, 0x52, 0x55, 0x55, 0x55, 0x48, 0x05, 0x56, 0xaa, 0xc0,
    		0xd2, 0x94, 0x94, 0xa5, 0x29, 0x49, 0x54, 0x95, 0x49, 0x2a, 0x92, 0x54, 0x10, 0xbb, 0x56, 0xa8,
    		0xfe, 0xd2, 0xa5, 0x52, 0xa5, 0x2a, 0x45, 0x49, 0x25, 0x49, 0x4a, 0xa2, 0x04, 0x2a, 0xa5, 0xa0,
    		0xff, 0xff, 0xda, 0xaa, 0x54, 0xa5, 0x29, 0x2a, 0xaa, 0xa4, 0xa9, 0x2a, 0x01, 0x0b, 0x52, 0xd0,
    		0xff, 0xff, 0xff, 0xff, 0xed, 0xa9, 0x54, 0xa4, 0x92, 0x55, 0x25, 0x55, 0x44, 0x45, 0x55, 0x40,
    		0xff, 0xff, 0xff, 0xff, 0xff, 0xff, 0xf6, 0xaa, 0x49, 0x2a, 0xaa, 0x48, 0x81, 0x25, 0x42, 0xe8,
    		0xff, 0xff, 0xff, 0xff, 0xff, 0xff, 0xff, 0xff, 0xff, 0xea, 0x92, 0xa6, 0x60, 0x02, 0x91, 0x20,
    		0xff, 0xfe, 0xff, 0xff, 0xff, 0xff, 0xff, 0xff, 0xff, 0xff, 0xff, 0xff, 0xe8, 0x52, 0xc8, 0x80,
    		0xfd, 0xdf, 0xef, 0xff, 0xff, 0xff, 0xff, 0xff, 0xff, 0xff, 0xff, 0xff, 0xf4, 0x01, 0x22, 0x50,
    		0xff, 0xff, 0xff, 0x77, 0xbf, 0xff, 0xff, 0xff, 0xff, 0xff, 0xff, 0xff, 0xfc, 0x00, 0x80, 0x00,
    		0xff, 0xfd, 0xff, 0xff, 0xff, 0xff, 0xdf, 0xff, 0xff, 0xff, 0xff, 0xff, 0xff, 0x80, 0x40, 0x03,
    		0xf7, 0xf7, 0xff, 0xff, 0xfd, 0xdd, 0xfe, 0xff, 0xff, 0xff, 0xff, 0xdd, 0xff, 0xfc, 0x01, 0x7f
    		};

    // Call the new initialization function
    EPD_Init();

    // --- LOAD IMAGE AND UPDATE ---
    EPD_Write_Command(0x24); // Command 0x24: Load image to Black/White RAM
    for(int i = 0; i < ALLSCREEN_BYTES; i++)
    {
//        EPD_Write_Data(image_buffer[i]); // Send 4000 bytes of image data
        EPD_Write_Data(0xFF); // Send 4000 bytes of image data
    }

    EPD_Update_and_Deepsleep_full_update();
}
/**
  * @brief  Read temperature and humidity from SHT45 sensor
  * @param  temperature: pointer to store temperature value
  * @param  humidity: pointer to store humidity value
  * @retval HAL status
  */
HAL_StatusTypeDef SHT45_Read_Temp_Humidity(float *temperature, float *humidity)
{
    uint8_t cmd = SHT45_CMD_MEASURE_HIGH_PRECISION;
    uint8_t rx_data[6];

    // Send measurement command
    HAL_StatusTypeDef status = HAL_I2C_Master_Transmit(&hi2c3, SHT45_I2C_ADDRESS << 1, &cmd, 1, 100);
    if (status != HAL_OK) {
        return status;
    }

    // Wait for measurement to complete (high precision takes ~10ms)
    HAL_Delay(15);

    // Read measurement data (6 bytes: 2 temp, 1 CRC, 2 humidity, 1 CRC)
    status = HAL_I2C_Master_Receive(&hi2c3, SHT45_I2C_ADDRESS << 1, rx_data, 6, 100);
    if (status != HAL_OK) {
        return status;
    }

    // Convert temperature data (first 2 bytes)
    uint16_t temp_raw = (rx_data[0] << 8) | rx_data[1];
    *temperature = -45.0f + 175.0f * ((float)temp_raw / 65535.0f);

    // Convert humidity data (bytes 3-4)
    uint16_t hum_raw = (rx_data[3] << 8) | rx_data[4];
    *humidity = -6.0f + 125.0f * ((float)hum_raw / 65535.0f);

    // Clamp humidity to valid range
    if (*humidity < 0.0f) *humidity = 0.0f;
    if (*humidity > 100.0f) *humidity = 100.0f;

    return HAL_OK;
}

/**
  * @brief  Update display with temperature and humidity data
  * @retval None
  */
void update_display_with_sensor_data(void)
{
    char temp_str[16];
    char hum_str[16];

    // Clear the screen
    lv_obj_clean(lv_scr_act());

    // Create table
    lv_obj_t *table = lv_table_create(lv_scr_act());

    // Set table size (3 rows, 2 columns)
    lv_table_set_row_cnt(table, 3);
    lv_table_set_col_cnt(table, 2);

    // Set column widths
    lv_table_set_col_width(table, 0, 100);  // Parameter column
    lv_table_set_col_width(table, 1, 120);  // Value column

    // Set table cell text
    lv_table_set_cell_value(table, 0, 0, "Parameter");
    lv_table_set_cell_value(table, 0, 1, "Value");

    snprintf(temp_str, sizeof(temp_str), "%.1f°C", current_temperature);
    snprintf(hum_str, sizeof(hum_str), "%.1f%%", current_humidity);

    lv_table_set_cell_value(table, 1, 0, "Temp.");
    lv_table_set_cell_value(table, 1, 1, temp_str);
    lv_table_set_cell_value(table, 2, 0, "Humidity");
    lv_table_set_cell_value(table, 2, 1, hum_str);

    // Set table style
    lv_obj_set_style_text_font(table, &lv_font_montserrat_16, 0);
    lv_obj_set_style_border_width(table, 2, 0);
    lv_obj_set_style_border_color(table, lv_color_black(), 0);
    lv_obj_set_style_pad_all(table, 8, 0);

    // Center the table on screen
    lv_obj_align(table, LV_ALIGN_CENTER, 0, 0);

    // Force display refresh
    lv_refr_now(NULL);
}

/**
  * @brief  Enter Stop 2 mode for 30 seconds to save power
  * @retval None
  */
void enter_stop2_mode(void)
{
    // Configure RTC wake-up for 30 seconds
    RTC_HandleTypeDef *hrtc_ptr = &hrtc;

    // Disable RTC interrupts temporarily
    HAL_NVIC_DisableIRQ(RTC_WKUP_IRQn);

    // Configure wake-up timer for 30 seconds
    // RTC clock is 32768 Hz (LSE), with DIV16 this becomes 2048 Hz
    // So for 30 seconds we need 30 * 2048 = 61440 cycles, so set to 61439 (0xF000-1)
    if (HAL_RTCEx_SetWakeUpTimer_IT(hrtc_ptr, 61439, RTC_WAKEUPCLOCK_RTCCLK_DIV16) != HAL_OK)
    {
        // If wake-up timer fails, use a short delay instead
        HAL_Delay(1000);
        return;
    }

    // Enable RTC wake-up interrupt
    HAL_NVIC_SetPriority(RTC_WKUP_IRQn, 0x00, 0x00);
    HAL_NVIC_EnableIRQ(RTC_WKUP_IRQn);

    // Clear wake-up flag
    __HAL_RTC_WAKEUPTIMER_CLEAR_FLAG(hrtc_ptr, RTC_FLAG_WUTF);

    // Enter Stop 2 mode
    HAL_PWREx_EnterSTOP2Mode(PWR_STOPENTRY_WFI);

    // After wake-up, reinitialize the HAL library to restore the clock
    // The system clock will be restored to MSI by default after wake-up from STOP2
    // We need to reconfigure it to the original configuration
    SystemClock_Config();

    // Disable wake-up timer after waking up
    HAL_RTCEx_DeactivateWakeUpTimer(hrtc_ptr);
}

/* USER CODE END 0 */

int main(void)
{

  /* MCU Configuration--------------------------------------------------------*/

  /* Reset of all peripherals, Initializes the Flash interface and the Systick. */
  HAL_Init();

  /* Configure the system clock */
  SystemClock_Config();

  /* Configure the peripherals common clocks */
  PeriphCommonClock_Config();

  /* Initialize all configured peripherals */
  MX_GPIO_Init();
  MX_DMA_Init();
  MX_SPI1_Init();
  MX_RTC_Init();
  MX_I2C3_Init();

  /* Initialize leds */
  BSP_LED_Init(LED_BLUE);
  BSP_LED_Init(LED_GREEN);
  BSP_LED_Init(LED_RED);

  /* Initialize USER push-button, will be used to trigger an interrupt each time it's pressed.*/
  BSP_PB_Init(BUTTON_SW1, BUTTON_MODE_EXTI);
  BSP_PB_Init(BUTTON_SW2, BUTTON_MODE_EXTI);
  BSP_PB_Init(BUTTON_SW3, BUTTON_MODE_EXTI);

  /* Initialize COM1 port (115200, 8 bits (7-bit data + 1 stop bit), no parity */
  BspCOMInit.BaudRate   = 115200;
  BspCOMInit.WordLength = COM_WORDLENGTH_8B;
  BspCOMInit.StopBits   = COM_STOPBITS_1;
  BspCOMInit.Parity     = COM_PARITY_NONE;
  BspCOMInit.HwFlowCtl  = COM_HWCONTROL_NONE;
  if (BSP_COM_Init(COM1, &BspCOMInit) != BSP_ERROR_NONE)
  {
    Error_Handler();
  }

  /* Infinite loop */
  /* USER CODE BEGIN WHILE */

  /* Initialize LVGL with EPD display */
  lv_epd_init();

  /* Initialize EPD hardware */
  EPD_Test_Sequence();

  EPD_Delay_ms(2000);
////
////  /* Create test UI */
//  lv_epd_create_test_ui();

  // Initial sensor read
  if (SHT45_Read_Temp_Humidity(&current_temperature, &current_humidity) == HAL_OK) {
      update_display_with_sensor_data();
  } else {
      // Display error message if sensor read fails
      lv_obj_t *error_table = lv_table_create(lv_scr_act());

      // Set table size (2 rows, 1 column)
      lv_table_set_row_cnt(error_table, 2);
      lv_table_set_col_cnt(error_table, 1);

      // Set table cell text
      lv_table_set_cell_value(error_table, 0, 0, "Status");
      lv_table_set_cell_value(error_table, 1, 0, "Sensor Error");

      // Set table style
      lv_obj_set_style_text_font(error_table, &lv_font_montserrat_16, 0);
      lv_obj_set_style_border_width(error_table, 2, 0);
      lv_obj_set_style_border_color(error_table, lv_color_black(), 0);
      lv_obj_set_style_pad_all(error_table, 8, 0);

      // Center the table on screen
      lv_obj_align(error_table, LV_ALIGN_CENTER, 0, 0);
  }

  last_sensor_read_time = HAL_GetTick();

	while (1) {

		// Read sensor data
		if (SHT45_Read_Temp_Humidity(&current_temperature, &current_humidity)
				== HAL_OK) {
			update_display_with_sensor_data();
		}
		lv_epd_task_handler();

		/* Enter Stop 2 mode for 30 seconds to save power */
		enter_stop2_mode();

		/* USER CODE END WHILE */

	}
}

void SystemClock_Config(void)
{
  RCC_OscInitTypeDef RCC_OscInitStruct = {0};
  RCC_ClkInitTypeDef RCC_ClkInitStruct = {0};

  /** Configure LSE Drive Capability
  */
  HAL_PWR_EnableBkUpAccess();
  __HAL_RCC_LSEDRIVE_CONFIG(RCC_LSEDRIVE_MEDIUMHIGH);

  /** Configure the main internal regulator output voltage
  */
  __HAL_PWR_VOLTAGESCALING_CONFIG(PWR_REGULATOR_VOLTAGE_SCALE1);

  /** Initializes the RCC Oscillators according to the specified parameters
  * in the RCC_OscInitTypeDef structure.
  */
  RCC_OscInitStruct.OscillatorType = RCC_OSCILLATORTYPE_HSI|RCC_OSCILLATORTYPE_HSE
                              |RCC_OSCILLATORTYPE_LSE|RCC_OSCILLATORTYPE_MSI;
  RCC_OscInitStruct.HSEState = RCC_HSE_ON;
  RCC_OscInitStruct.LSEState = RCC_LSE_ON;
  RCC_OscInitStruct.HSIState = RCC_HSI_ON;
  RCC_OscInitStruct.MSIState = RCC_MSI_ON;
  RCC_OscInitStruct.HSICalibrationValue = RCC_HSICALIBRATION_DEFAULT;
  RCC_OscInitStruct.MSICalibrationValue = RCC_MSICALIBRATION_DEFAULT;
  RCC_OscInitStruct.MSIClockRange = RCC_MSIRANGE_10;
  RCC_OscInitStruct.PLL.PLLState = RCC_PLL_NONE;
  if (HAL_RCC_OscConfig(&RCC_OscInitStruct) != HAL_OK)
  {
    Error_Handler();
  }

  /** Configure the SYSCLKSource, HCLK, PCLK1 and PCLK2 clocks dividers
  */
  RCC_ClkInitStruct.ClockType = RCC_CLOCKTYPE_HCLK4|RCC_CLOCKTYPE_HCLK2
                              |RCC_CLOCKTYPE_HCLK|RCC_CLOCKTYPE_SYSCLK
                              |RCC_CLOCKTYPE_PCLK1|RCC_CLOCKTYPE_PCLK2;
  RCC_ClkInitStruct.SYSCLKSource = RCC_SYSCLKSOURCE_MSI;
  RCC_ClkInitStruct.AHBCLKDivider = RCC_SYSCLK_DIV1;
  RCC_ClkInitStruct.APB1CLKDivider = RCC_HCLK_DIV1;
  RCC_ClkInitStruct.APB2CLKDivider = RCC_HCLK_DIV1;
  RCC_ClkInitStruct.AHBCLK2Divider = RCC_SYSCLK_DIV1;
  RCC_ClkInitStruct.AHBCLK4Divider = RCC_SYSCLK_DIV1;

  if (HAL_RCC_ClockConfig(&RCC_ClkInitStruct, FLASH_LATENCY_1) != HAL_OK)
  {
    Error_Handler();
  }

  /** Enables the Clock Security System
  */
  HAL_RCCEx_EnableLSECSS();
}

void PeriphCommonClock_Config(void)
{
  RCC_PeriphCLKInitTypeDef PeriphClkInitStruct = {0};

  /** Initializes the peripherals clock
  */
  PeriphClkInitStruct.PeriphClockSelection = RCC_PERIPHCLK_SMPS;
  PeriphClkInitStruct.SmpsClockSelection = RCC_SMPSCLKSOURCE_HSI;
  PeriphClkInitStruct.SmpsDivSelection = RCC_SMPSCLKDIV_RANGE0;

  if (HAL_RCCEx_PeriphCLKConfig(&PeriphClkInitStruct) != HAL_OK)
  {
    Error_Handler();
  }
}

static void MX_I2C3_Init(void)
{

  hi2c3.Instance = I2C3;
  hi2c3.Init.Timing = 0x00B07CB4;
  hi2c3.Init.OwnAddress1 = 0;
  hi2c3.Init.AddressingMode = I2C_ADDRESSINGMODE_7BIT;
  hi2c3.Init.DualAddressMode = I2C_DUALADDRESS_DISABLE;
  hi2c3.Init.OwnAddress2 = 0;
  hi2c3.Init.OwnAddress2Masks = I2C_OA2_NOMASK;
  hi2c3.Init.GeneralCallMode = I2C_GENERALCALL_DISABLE;
  hi2c3.Init.NoStretchMode = I2C_NOSTRETCH_DISABLE;
  if (HAL_I2C_Init(&hi2c3) != HAL_OK)
  {
    Error_Handler();
  }

  /** Configure Analogue filter
  */
  if (HAL_I2CEx_ConfigAnalogFilter(&hi2c3, I2C_ANALOGFILTER_ENABLE) != HAL_OK)
  {
    Error_Handler();
  }

  /** Configure Digital filter
  */
  if (HAL_I2CEx_ConfigDigitalFilter(&hi2c3, 0) != HAL_OK)
  {
    Error_Handler();
  }

}

static void MX_RTC_Init(void)
{

  /** Initialize RTC Only
  */
  hrtc.Instance = RTC;
  hrtc.Init.HourFormat = RTC_HOURFORMAT_24;
  hrtc.Init.AsynchPrediv = 127;
  hrtc.Init.SynchPrediv = 255;
  hrtc.Init.OutPut = RTC_OUTPUT_DISABLE;
  hrtc.Init.OutPutPolarity = RTC_OUTPUT_POLARITY_HIGH;
  hrtc.Init.OutPutType = RTC_OUTPUT_TYPE_OPENDRAIN;
  hrtc.Init.OutPutRemap = RTC_OUTPUT_REMAP_NONE;
  if (HAL_RTC_Init(&hrtc) != HAL_OK)
  {
    Error_Handler();
  }

  /** Enable the WakeUp
  */
  if (HAL_RTCEx_SetWakeUpTimer_IT(&hrtc, 0, RTC_WAKEUPCLOCK_RTCCLK_DIV16) != HAL_OK)
  {
    Error_Handler();
  }

}

static void MX_SPI1_Init(void)
{

  /* SPI1 parameter configuration*/
  hspi1.Instance = SPI1;
  hspi1.Init.Mode = SPI_MODE_MASTER;
  hspi1.Init.Direction = SPI_DIRECTION_2LINES;
  hspi1.Init.DataSize = SPI_DATASIZE_8BIT;
  hspi1.Init.CLKPolarity = SPI_POLARITY_LOW;
  hspi1.Init.CLKPhase = SPI_PHASE_1EDGE;
  hspi1.Init.NSS = SPI_NSS_SOFT;
  hspi1.Init.BaudRatePrescaler = SPI_BAUDRATEPRESCALER_2;
  hspi1.Init.FirstBit = SPI_FIRSTBIT_MSB;
  hspi1.Init.TIMode = SPI_TIMODE_DISABLE;
  hspi1.Init.CRCCalculation = SPI_CRCCALCULATION_DISABLE;
  hspi1.Init.CRCPolynomial = 7;
  hspi1.Init.CRCLength = SPI_CRC_LENGTH_DATASIZE;
  hspi1.Init.NSSPMode = SPI_NSS_PULSE_DISABLE;
  if (HAL_SPI_Init(&hspi1) != HAL_OK)
  {
    Error_Handler();
  }

}

static void MX_DMA_Init(void)
{

  /* DMA controller clock enable */
  __HAL_RCC_DMAMUX1_CLK_ENABLE();
  __HAL_RCC_DMA1_CLK_ENABLE();

  /* DMA interrupt init */
  /* DMA1_Channel1_IRQn interrupt configuration */
  HAL_NVIC_SetPriority(DMA1_Channel1_IRQn, 0, 0);
  HAL_NVIC_EnableIRQ(DMA1_Channel1_IRQn);

}

static void MX_GPIO_Init(void)
{
  GPIO_InitTypeDef GPIO_InitStruct = {0};

  /* GPIO Ports Clock Enable */
  __HAL_RCC_GPIOC_CLK_ENABLE();
  __HAL_RCC_GPIOB_CLK_ENABLE();
  __HAL_RCC_GPIOA_CLK_ENABLE();

  /*Configure GPIO pin Output Level */
  HAL_GPIO_WritePin(GPIOB, CS_Pin|RST_Pin, GPIO_PIN_SET);

  /*Configure GPIO pin Output Level */
  HAL_GPIO_WritePin(DC_GPIO_Port, DC_Pin, GPIO_PIN_RESET);

  /*Configure GPIO pins : CS_Pin DC_Pin */
  GPIO_InitStruct.Pin = CS_Pin|DC_Pin;
  GPIO_InitStruct.Mode = GPIO_MODE_OUTPUT_PP;
  GPIO_InitStruct.Pull = GPIO_NOPULL;
  GPIO_InitStruct.Speed = GPIO_SPEED_FREQ_VERY_HIGH;
  HAL_GPIO_Init(GPIOB, &GPIO_InitStruct);

  /*Configure GPIO pin : BUSY_Pin */
  GPIO_InitStruct.Pin = BUSY_Pin;
  GPIO_InitStruct.Mode = GPIO_MODE_INPUT;
  GPIO_InitStruct.Pull = GPIO_NOPULL;
  HAL_GPIO_Init(BUSY_GPIO_Port, &GPIO_InitStruct);

  /*Configure GPIO pins : USB_DM_Pin USB_DP_Pin */
  GPIO_InitStruct.Pin = USB_DM_Pin|USB_DP_Pin;
  GPIO_InitStruct.Mode = GPIO_MODE_AF_PP;
  GPIO_InitStruct.Pull = GPIO_NOPULL;
  GPIO_InitStruct.Speed = GPIO_SPEED_FREQ_LOW;
  GPIO_InitStruct.Alternate = GPIO_AF10_USB;
  HAL_GPIO_Init(GPIOA, &GPIO_InitStruct);

  /*Configure GPIO pin : RST_Pin */
  GPIO_InitStruct.Pin = RST_Pin;
  GPIO_InitStruct.Mode = GPIO_MODE_OUTPUT_PP;
  GPIO_InitStruct.Pull = GPIO_NOPULL;
  GPIO_InitStruct.Speed = GPIO_SPEED_FREQ_LOW;
  HAL_GPIO_Init(RST_GPIO_Port, &GPIO_InitStruct);

  /**/
  __HAL_SYSCFG_FASTMODEPLUS_ENABLE(SYSCFG_FASTMODEPLUS_PB8);

  /**/
  __HAL_SYSCFG_FASTMODEPLUS_ENABLE(SYSCFG_FASTMODEPLUS_PB9);

}

void Error_Handler(void)
{
  __disable_irq();
  while (1)
  {
  }
}
